AUTOSAR XML (schema 4-0-3)
package /ComponentTypes
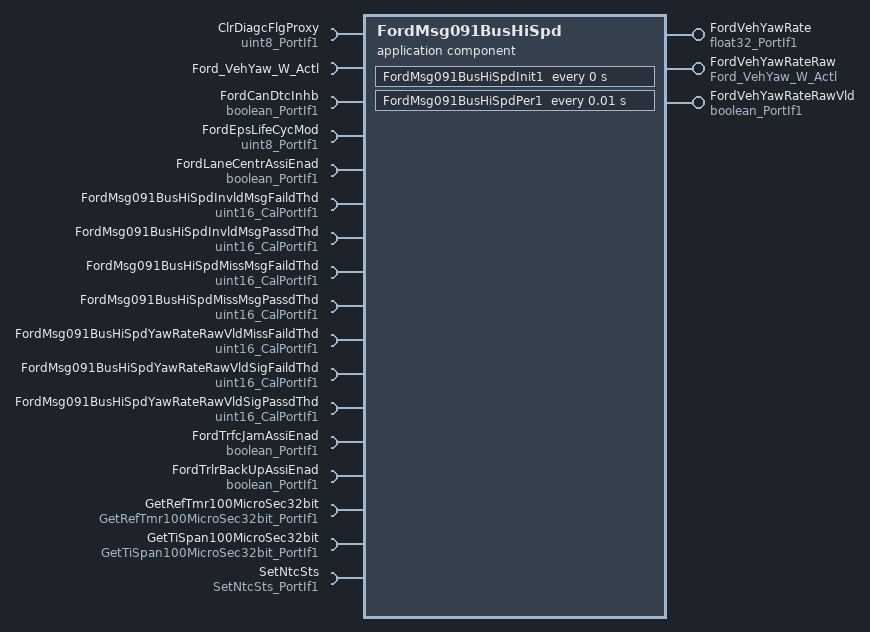
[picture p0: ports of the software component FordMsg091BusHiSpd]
  application sw component type FordMsg091BusHiSpd
    provide port FordVehYawRate: nonqueued-sender-com-spec{data-element=Val, init-value=6.6066}, provided-interface=float32_PortIf1
    provide port FordVehYawRateRaw: nonqueued-sender-com-spec{data-element=Ford_VehYaw_W_Actl, init-value=65534}, provided-interface=Ford_VehYaw_W_Actl
    provide port FordVehYawRateRawVld: nonqueued-sender-com-spec{data-element=Logl, init-value=0}, provided-interface=boolean_PortIf1
    17 x require port:
      ClrDiagcFlgProxy: nonqueued-receiver-com-spec{data-element=Val, filter=data-filter-type=ALWAYS, init-value=0}, required-interface=uint8_PortIf1
      Ford_VehYaw_W_Actl: nonqueued-receiver-com-spec{data-element=Ford_VehYaw_W_Actl, filter=data-filter-type=ALWAYS, init-value=65534}, required-interface=Ford_VehYaw_W_Actl
      FordCanDtcInhb: nonqueued-receiver-com-spec{data-element=Logl, filter=data-filter-type=ALWAYS, init-value=1}, required-interface=boolean_PortIf1
      FordEpsLifeCycMod: nonqueued-receiver-com-spec{data-element=Val, filter=data-filter-type=ALWAYS, init-value=0}, required-interface=uint8_PortIf1
      FordLaneCentrAssiEnad: nonqueued-receiver-com-spec{data-element=Logl, filter=data-filter-type=ALWAYS, init-value=0}, required-interface=boolean_PortIf1
      FordMsg091BusHiSpdInvldMsgFaildThd: parameter-require-com-spec{init-value=0, parameter=Val}, required-interface=uint16_CalPortIf1
      FordMsg091BusHiSpdInvldMsgPassdThd: parameter-require-com-spec{init-value=0, parameter=Val}, required-interface=uint16_CalPortIf1
      FordMsg091BusHiSpdMissMsgFaildThd: parameter-require-com-spec{init-value=100, parameter=Val}, required-interface=uint16_CalPortIf1
      FordMsg091BusHiSpdMissMsgPassdThd: parameter-require-com-spec{init-value=0, parameter=Val}, required-interface=uint16_CalPortIf1
      FordMsg091BusHiSpdYawRateRawVldMissFaildThd: parameter-require-com-spec{init-value=100, parameter=Val}, required-interface=uint16_CalPortIf1
      FordMsg091BusHiSpdYawRateRawVldSigFaildThd: parameter-require-com-spec{init-value=0, parameter=Val}, required-interface=uint16_CalPortIf1
      FordMsg091BusHiSpdYawRateRawVldSigPassdThd: parameter-require-com-spec{init-value=5000, parameter=Val}, required-interface=uint16_CalPortIf1
      FordTrfcJamAssiEnad: nonqueued-receiver-com-spec{data-element=Logl, filter=data-filter-type=ALWAYS, init-value=0}, required-interface=boolean_PortIf1
      FordTrlrBackUpAssiEnad: nonqueued-receiver-com-spec{data-element=Logl, filter=data-filter-type=ALWAYS, init-value=0}, required-interface=boolean_PortIf1
      GetRefTmr100MicroSec32bit: required-com-specs=[Oper, Oper], required-interface=GetRefTmr100MicroSec32bit_PortIf1
      GetTiSpan100MicroSec32bit: required-com-specs=[Oper, Oper], required-interface=GetTiSpan100MicroSec32bit_PortIf1
      SetNtcSts: required-com-specs=[Oper, Oper], required-interface=SetNtcSts_PortIf1
    behavior FordMsg091BusHiSpd_InternalBehavior
      ar-typed-per-instance-memorys:
        13 x data, all with sw-calibration-access=READ-ONLY:
          ClrDiagcFlgProxyPrev: type=uint8
          FirstTranVldFlg: type=boolean
          FordVehMsg091Miss: type=boolean
          FordVehYawRatePrev: type=float32
          FordVehYawRateRawPrev: type=uint16
          FordVehYawRateRawVldFaildRefTi: type=uint32
          FordVehYawRateRawVldMissRefTi: type=uint32
          FordVehYawRateRawVldPassdRefTi: type=uint32
          FordVehYawRateRawVldPrev: type=boolean
          InvldMsgFaildRefTi: type=uint32
          InvldMsgPassdRefTi: type=uint32
          MissMsgFaildRefTi: type=uint32
          MissMsgPassdRefTi: type=uint32
      timing event FordMsg091BusHiSpd_InitEvent: start-on-event=FordMsg091BusHiSpdInit1, period=0
      timing event TMT_FordMsg414BusHiSpdPer1: start-on-event=FordMsg091BusHiSpdPer1, period=0.01
      port-api-options:
        enable-take-address=false, indirect-api=false, port=ClrDiagcFlgProxy
        enable-take-address=false, indirect-api=false, port=Ford_VehYaw_W_Actl
        enable-take-address=false, indirect-api=false, port=FordCanDtcInhb
        enable-take-address=false, indirect-api=false, port=FordEpsLifeCycMod
        enable-take-address=false, indirect-api=false, port=FordLaneCentrAssiEnad
        enable-take-address=false, indirect-api=false, port=FordMsg091BusHiSpdInvldMsgFaildThd
        enable-take-address=false, indirect-api=false, port=FordMsg091BusHiSpdInvldMsgPassdThd
        enable-take-address=false, indirect-api=false, port=FordMsg091BusHiSpdMissMsgFaildThd
        enable-take-address=false, indirect-api=false, port=FordMsg091BusHiSpdMissMsgPassdThd
        enable-take-address=false, indirect-api=false, port=FordMsg091BusHiSpdYawRateRawVldMissFaildThd
        enable-take-address=false, indirect-api=false, port=FordMsg091BusHiSpdYawRateRawVldSigFaildThd
        enable-take-address=false, indirect-api=false, port=FordMsg091BusHiSpdYawRateRawVldSigPassdThd
        enable-take-address=false, indirect-api=false, port=FordTrfcJamAssiEnad
        enable-take-address=false, indirect-api=false, port=FordTrlrBackUpAssiEnad
        enable-take-address=false, indirect-api=false, port=FordVehYawRate
        enable-take-address=false, indirect-api=false, port=FordVehYawRateRaw
        enable-take-address=false, indirect-api=false, port=FordVehYawRateRawVld
        enable-take-address=false, indirect-api=false, port=GetRefTmr100MicroSec32bit
        enable-take-address=false, indirect-api=false, port=GetTiSpan100MicroSec32bit
        enable-take-address=false, indirect-api=false, port=SetNtcSts
      runnable FordMsg091BusHiSpdInit1
        sync call SC_GetRefTmr100MicroSec32bit_Oper: operation=GetRefTmr100MicroSec32bit.Oper, timeout=0
      runnable FordMsg091BusHiSpdPer1
        data-receive-point-by-arguments:
          7 x access:
            REC_ClrDiagcFlgProxy_Val: accessed-variable=ClrDiagcFlgProxy.Val
            REC_Ford_VehYaw_W_Actl_Ford_VehYaw_W_Actl: accessed-variable=Ford_VehYaw_W_Actl.Ford_VehYaw_W_Actl
            REC_FordCanDtcInhb_Logl: accessed-variable=FordCanDtcInhb.Logl
            REC_FordEpsLifeCycMod_Val: accessed-variable=FordEpsLifeCycMod.Val
            REC_FordLaneCentrAssiEnad_Logl: accessed-variable=FordLaneCentrAssiEnad.Logl
            REC_FordTrfcJamAssiEnad_Logl: accessed-variable=FordTrfcJamAssiEnad.Logl
            REC_FordTrlrBackUpAssiEnad_Logl: accessed-variable=FordTrlrBackUpAssiEnad.Logl
        data-send-points:
          access SEND_FordVehYawRate_Val: accessed-variable=FordVehYawRate.Val
          access SEND_FordVehYawRateRaw_Ford_VehYaw_W_Actl: accessed-variable=FordVehYawRateRaw.Ford_VehYaw_W_Actl
          access SEND_FordVehYawRateRawVld_Logl: accessed-variable=FordVehYawRateRawVld.Logl
        sync call SC_GetRefTmr100MicroSec32bit_Oper: operation=GetRefTmr100MicroSec32bit.Oper, timeout=0
        sync call SC_GetTiSpan100MicroSec32bit_Oper: operation=GetTiSpan100MicroSec32bit.Oper, timeout=0
        sync call SC_SetNtcSts_Oper: operation=SetNtcSts.Oper, timeout=0
  swc implementation FordMsg091BusHiSpd_Implementation: behavior=FordMsg091BusHiSpd_InternalBehavior
    code-descriptors:
      code Default: artifact-descriptors=autosar-engineering-object={short-label=Default, category=SWSRC}
